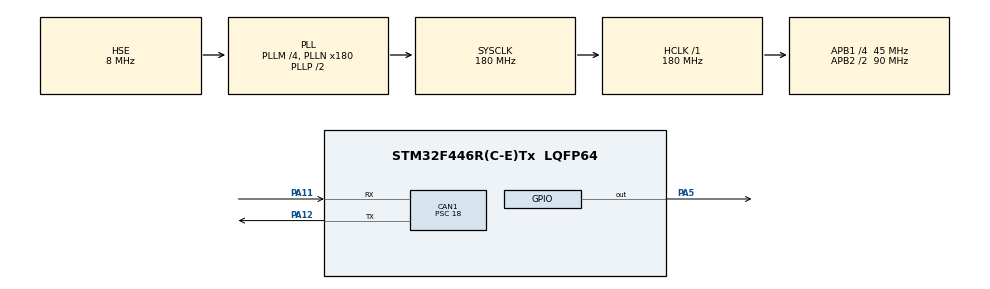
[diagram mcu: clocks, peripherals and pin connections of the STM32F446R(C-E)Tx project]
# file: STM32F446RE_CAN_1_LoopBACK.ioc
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CAN1.BS1=CAN_BS1_2TQ
CAN1.BS2=CAN_BS2_2TQ
CAN1.CalculateBaudRate=500000
CAN1.CalculateTimeBit=2000
CAN1.CalculateTimeQuantum=400.0
CAN1.Mode=CAN_MODE_LOOPBACK
CAN1.Prescaler=18
Mcu.Family=STM32F4
Mcu.Name=STM32F446R(C-E)Tx
Mcu.Package=LQFP64
NVIC.PriorityGroup=NVIC_PRIORITYGROUP_4
PA11.Mode=CAN_Activate
PA11.Signal=CAN1_RX
PA12.Mode=CAN_Activate
PA12.Signal=CAN1_TX
PA13.Mode=Serial_Wire
PA13.Signal=SYS_JTMS-SWDIO
PA14.Mode=Serial_Wire
PA14.Signal=SYS_JTCK-SWCLK
PA5.Signal=GPIO_Output
PH0-OSC_IN.Mode=HSE-External-Oscillator
PH0-OSC_IN.Signal=RCC_OSC_IN
PH1-OSC_OUT.Mode=HSE-External-Oscillator
PH1-OSC_OUT.Signal=RCC_OSC_OUT
ProjectManager.HeapSize=0x200
ProjectManager.StackSize=0x400
ProjectManager.TargetToolchain=STM32CubeIDE
RCC.AHBFreq_Value=180000000
RCC.APB1CLKDivider=RCC_HCLK_DIV4
RCC.APB1Freq_Value=45000000
RCC.APB1TimFreq_Value=90000000
RCC.APB2CLKDivider=RCC_HCLK_DIV2
RCC.APB2Freq_Value=90000000
RCC.APB2TimFreq_Value=180000000
RCC.CortexFreq_Value=180000000
RCC.HCLKFreq_Value=180000000
RCC.HSE_VALUE=8000000
RCC.PLLM=4
RCC.PLLN=180
RCC.PLLSourceVirtual=RCC_PLLSOURCE_HSE
RCC.SYSCLKFreq_VALUE=180000000
RCC.SYSCLKSource=RCC_SYSCLKSOURCE_PLLCLK
RCC.USBFreq_Value=180000000
RCC.VCOOutputFreq_Value=360000000
board=custom

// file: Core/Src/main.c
/* USER CODE BEGIN Header */
/**
  ******************************************************************************
  * @file           : main.c
  * @brief          : Main program body
  ******************************************************************************
  * @attention
  *
  * Copyright (c) 2024 STMicroelectronics.
  * All rights reserved.
  *
  * This software is licensed under terms that can be found in the LICENSE file
  * in the root directory of this software component.
  * If no LICENSE file comes with this software, it is provided AS-IS.
  *
  ******************************************************************************
  */
/* USER CODE END Header */
#include "main.h"

CAN_HandleTypeDef hcan1;

/* USER CODE BEGIN PV */
CAN_HandleTypeDef     CanHandle;
CAN_TxHeaderTypeDef   TxHeader;
CAN_RxHeaderTypeDef   RxHeader;
uint8_t               TxData[8];
uint8_t               RxData[8];
uint32_t              TxMailbox;
/* USER CODE END PV */

void SystemClock_Config(void);
static void MX_GPIO_Init(void);
static void MX_CAN1_Init(void);

/* USER CODE BEGIN 0 */
HAL_StatusTypeDef CAN_Polling(void)
{
  CAN_FilterTypeDef  sFilterConfig;

  /*##-1- Configure the CAN peripheral #######################################*/
  CanHandle.Instance = CAN1;

  CanHandle.Init.TimeTriggeredMode = DISABLE;
  CanHandle.Init.AutoBusOff = DISABLE;
  CanHandle.Init.AutoWakeUp = DISABLE;
  CanHandle.Init.AutoRetransmission = ENABLE;
  CanHandle.Init.ReceiveFifoLocked = DISABLE;
  CanHandle.Init.TransmitFifoPriority = DISABLE;
  CanHandle.Init.Mode = CAN_MODE_LOOPBACK;
  CanHandle.Init.SyncJumpWidth = CAN_SJW_1TQ;
  CanHandle.Init.TimeSeg1 = CAN_BS1_6TQ;
  CanHandle.Init.TimeSeg2 = CAN_BS2_2TQ;
  CanHandle.Init.Prescaler = 5;

  if(HAL_CAN_Init(&CanHandle) != HAL_OK)
  {
    /* Initialization Error */
    Error_Handler();
  }

  /*##-2- Configure the CAN Filter ###########################################*/
  sFilterConfig.FilterBank = 0;
  sFilterConfig.FilterMode = CAN_FILTERMODE_IDMASK;
  sFilterConfig.FilterScale = CAN_FILTERSCALE_32BIT;
  sFilterConfig.FilterIdHigh = 0x0000;
  sFilterConfig.FilterIdLow = 0x0000;
  sFilterConfig.FilterMaskIdHigh = 0x0000;
  sFilterConfig.FilterMaskIdLow = 0x0000;
  sFilterConfig.FilterFIFOAssignment = CAN_RX_FIFO0;
  sFilterConfig.FilterActivation = ENABLE;
  sFilterConfig.SlaveStartFilterBank = 14;

  if(HAL_CAN_ConfigFilter(&CanHandle, &sFilterConfig) != HAL_OK)
  {
    /* Filter configuration Error */
    Error_Handler();
  }

  /*##-3- Start the CAN peripheral ###########################################*/
  if (HAL_CAN_Start(&CanHandle) != HAL_OK)
  {
    /* Start Error */
    Error_Handler();
  }

  /*##-4- Start the Transmission process #####################################*/
  TxHeader.StdId = 0x11;
  TxHeader.RTR = CAN_RTR_DATA;
  TxHeader.IDE = CAN_ID_STD;
  TxHeader.DLC = 8;
  TxHeader.TransmitGlobalTime = DISABLE;
  TxData[0] = 1;
  TxData[1] = 2;
  TxData[2] = 3;
  TxData[3] = 4;
  TxData[4] = 5;
  TxData[5] = 6;
  TxData[6] = 7;
  TxData[7] = 8;

  /* Request transmission */
  if(HAL_CAN_AddTxMessage(&CanHandle, &TxHeader, TxData, &TxMailbox) != HAL_OK)
  {
    /* Transmission request Error */
    Error_Handler();
  }

  /* Wait transmission complete */
  while(HAL_CAN_GetTxMailboxesFreeLevel(&CanHandle) != 3) {}

  /*##-5- Start the Reception process ########################################*/
  if(HAL_CAN_GetRxFifoFillLevel(&CanHandle, CAN_RX_FIFO0) != 1)
  {
    /* Reception Missing */
    Error_Handler();
  }

  if(HAL_CAN_GetRxMessage(&CanHandle, CAN_RX_FIFO0, &RxHeader, RxData) != HAL_OK)
  {
    /* Reception Error */
    Error_Handler();
  }

  if((RxHeader.StdId != 0x11)                     ||
     (RxHeader.RTR != CAN_RTR_DATA)               ||
     (RxHeader.IDE != CAN_ID_STD)                 ||
     (RxHeader.DLC != 8) )

  {
    /* Rx message Error */
    return HAL_ERROR;
  }

  return HAL_OK; /* Test Passed */
}
/* USER CODE END 0 */

int main(void)
{

  /* MCU Configuration--------------------------------------------------------*/

  /* Reset of all peripherals, Initializes the Flash interface and the Systick. */
  HAL_Init();

  /* Configure the system clock */
  SystemClock_Config();

  /* Initialize all configured peripherals */
  MX_GPIO_Init();
  MX_CAN1_Init();

  /* Infinite loop */
  /* USER CODE BEGIN WHILE */
  while (1)
  {
	  if(CAN_Polling() == HAL_OK) {

	 	  HAL_GPIO_TogglePin(GPIOA, GPIO_PIN_5);
	 	  HAL_Delay(100);
	   }
	   else{

	 	  HAL_GPIO_TogglePin(GPIOA, GPIO_PIN_5);
		  HAL_Delay(500);
	   }
    /* USER CODE END WHILE */

  }
}

void SystemClock_Config(void)
{
  RCC_OscInitTypeDef RCC_OscInitStruct = {0};
  RCC_ClkInitTypeDef RCC_ClkInitStruct = {0};

  /** Configure the main internal regulator output voltage
  */
  __HAL_RCC_PWR_CLK_ENABLE();
  __HAL_PWR_VOLTAGESCALING_CONFIG(PWR_REGULATOR_VOLTAGE_SCALE1);

  /** Initializes the RCC Oscillators according to the specified parameters
  * in the RCC_OscInitTypeDef structure.
  */
  RCC_OscInitStruct.OscillatorType = RCC_OSCILLATORTYPE_HSE;
  RCC_OscInitStruct.HSEState = RCC_HSE_ON;
  RCC_OscInitStruct.PLL.PLLState = RCC_PLL_ON;
  RCC_OscInitStruct.PLL.PLLSource = RCC_PLLSOURCE_HSE;
  RCC_OscInitStruct.PLL.PLLM = 4;
  RCC_OscInitStruct.PLL.PLLN = 180;
  RCC_OscInitStruct.PLL.PLLP = RCC_PLLP_DIV2;
  RCC_OscInitStruct.PLL.PLLQ = 2;
  RCC_OscInitStruct.PLL.PLLR = 2;
  if (HAL_RCC_OscConfig(&RCC_OscInitStruct) != HAL_OK)
  {
    Error_Handler();
  }

  /** Activate the Over-Drive mode
  */
  if (HAL_PWREx_EnableOverDrive() != HAL_OK)
  {
    Error_Handler();
  }

  /** Initializes the CPU, AHB and APB buses clocks
  */
  RCC_ClkInitStruct.ClockType = RCC_CLOCKTYPE_HCLK|RCC_CLOCKTYPE_SYSCLK
                              |RCC_CLOCKTYPE_PCLK1|RCC_CLOCKTYPE_PCLK2;
  RCC_ClkInitStruct.SYSCLKSource = RCC_SYSCLKSOURCE_PLLCLK;
  RCC_ClkInitStruct.AHBCLKDivider = RCC_SYSCLK_DIV1;
  RCC_ClkInitStruct.APB1CLKDivider = RCC_HCLK_DIV4;
  RCC_ClkInitStruct.APB2CLKDivider = RCC_HCLK_DIV2;

  if (HAL_RCC_ClockConfig(&RCC_ClkInitStruct, FLASH_LATENCY_5) != HAL_OK)
  {
    Error_Handler();
  }
}

static void MX_CAN1_Init(void)
{

  hcan1.Instance = CAN1;
  hcan1.Init.Prescaler = 18;
  hcan1.Init.Mode = CAN_MODE_LOOPBACK;
  hcan1.Init.SyncJumpWidth = CAN_SJW_1TQ;
  hcan1.Init.TimeSeg1 = CAN_BS1_2TQ;
  hcan1.Init.TimeSeg2 = CAN_BS2_2TQ;
  hcan1.Init.TimeTriggeredMode = DISABLE;
  hcan1.Init.AutoBusOff = DISABLE;
  hcan1.Init.AutoWakeUp = DISABLE;
  hcan1.Init.AutoRetransmission = DISABLE;
  hcan1.Init.ReceiveFifoLocked = DISABLE;
  hcan1.Init.TransmitFifoPriority = DISABLE;
  if (HAL_CAN_Init(&hcan1) != HAL_OK)
  {
    Error_Handler();
  }

}

static void MX_GPIO_Init(void)
{
  GPIO_InitTypeDef GPIO_InitStruct = {0};

  /* GPIO Ports Clock Enable */
  __HAL_RCC_GPIOH_CLK_ENABLE();
  __HAL_RCC_GPIOA_CLK_ENABLE();

  /*Configure GPIO pin Output Level */
  HAL_GPIO_WritePin(GPIOA, GPIO_PIN_5, GPIO_PIN_RESET);

  /*Configure GPIO pin : PA5 */
  GPIO_InitStruct.Pin = GPIO_PIN_5;
  GPIO_InitStruct.Mode = GPIO_MODE_OUTPUT_PP;
  GPIO_InitStruct.Pull = GPIO_NOPULL;
  GPIO_InitStruct.Speed = GPIO_SPEED_FREQ_LOW;
  HAL_GPIO_Init(GPIOA, &GPIO_InitStruct);

}

void Error_Handler(void)
{
  __disable_irq();
  while (1)
  {
  }
}
